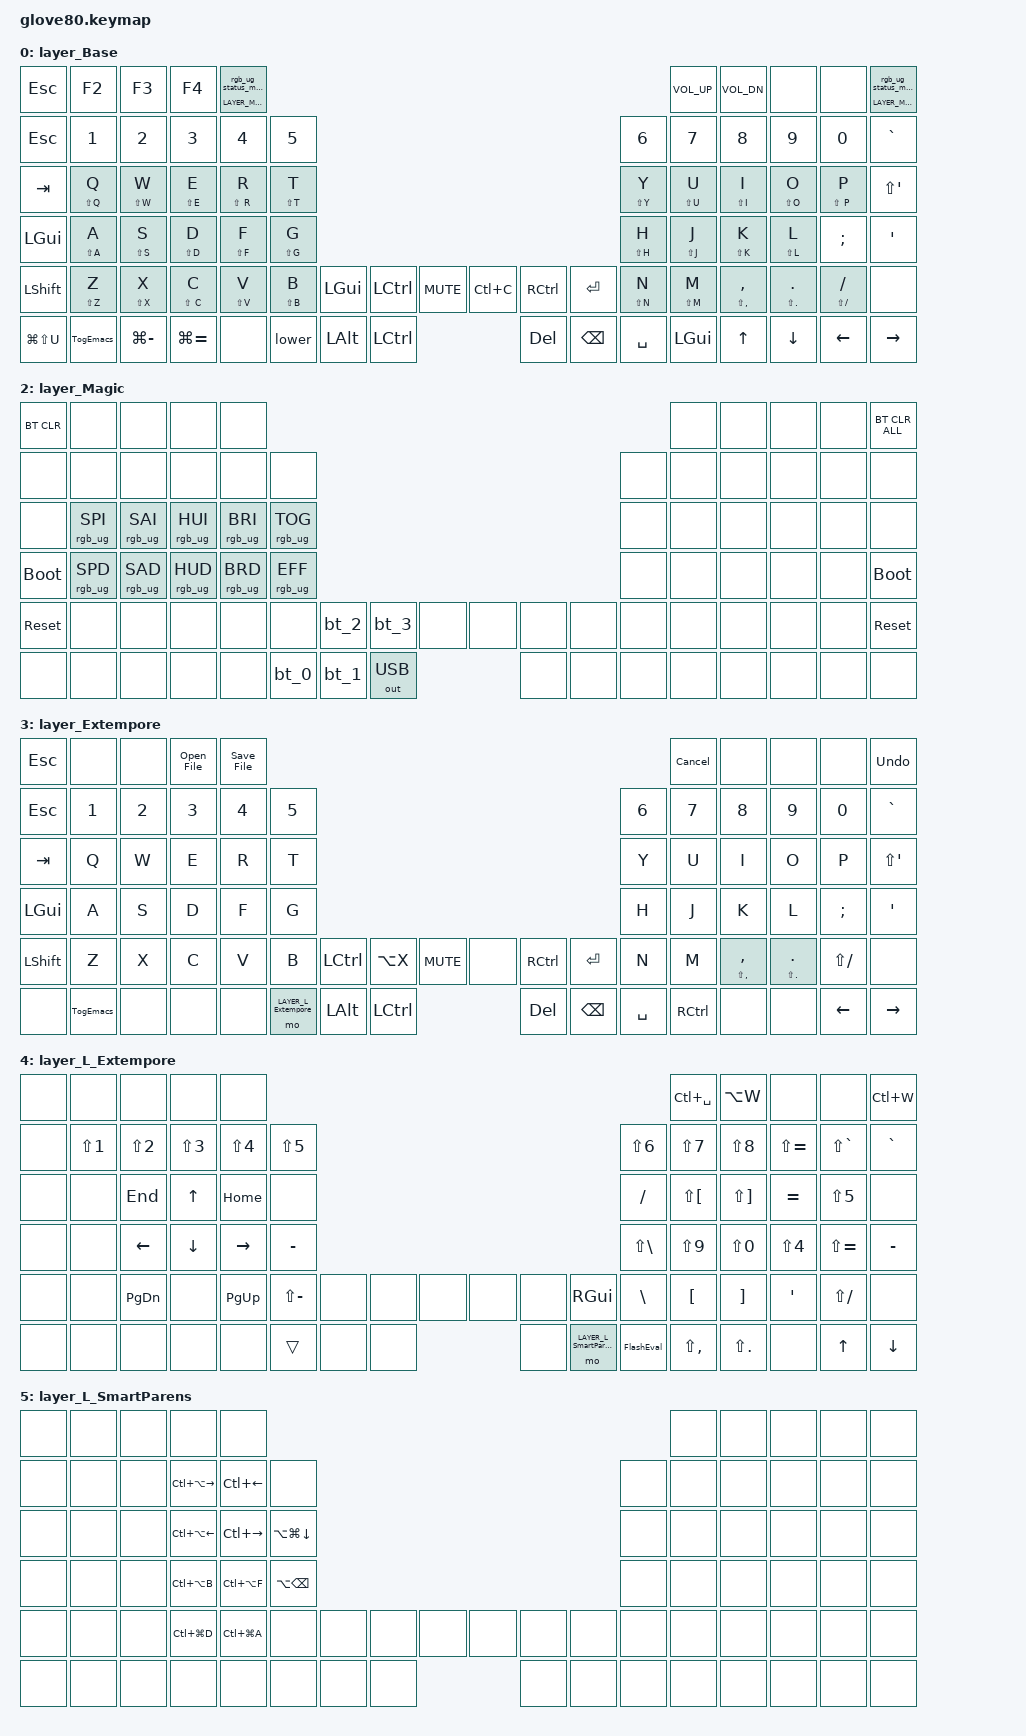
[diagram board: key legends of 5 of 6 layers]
/*
 * Copyright (c) 2020 The ZMK Contributors
 * Copyright (c) 2025 Innaworks Development Limited, trading as MoErgo
 *
 * SPDX-License-Identifier: MIT
 */


/* THIS FILE WAS GENERATED BY GLOVE80 LAYOUT EDITOR
 *
 * This file was generated automatically. You may or may not want to
 * edit it directly.
 *
 *
 * DLM: This is working now Thu Oct 22 21:34:18 AEDT 2026
 *      This has to be processed through the GitHub Repo.
 *      SmartParens modes in this version
 */

#include <behaviors.dtsi>
/* Include all behavior includes needed */
#include <dt-bindings/zmk/outputs.h>
#include <dt-bindings/zmk/keys.h>
#include <dt-bindings/zmk/bt.h>
#include <dt-bindings/zmk/rgb.h>
//#include <dt-bindings/zmk/rgb_colors.h>

/* On demand includes */


/* Helper Macros, based on https://github.com/urob/zmk-helpers/ */

#pragma once

#define ZMK_HELPER_STRINGIFY(x) #x

// Preprocessor mechanism to overload macros, cf. https://stackoverflow.com/a/27051616/6114651
#define VARGS_(_10, _9, _8, _7, _6, _5, _4, _3, _2, _1, N, ...) N
#define VARGS(...) VARGS_(__VA_ARGS__, 10, 9, 8, 7, 6, 5, 4, 3, 2, 1, 0)
#define CONCAT_(a, b) a##b
#define CONCAT(a, b) CONCAT_(a, b)

#define ZMK_BEHAVIOR_CORE_tap_dance  \
    compatible = "zmk,behavior-tap-dance"; \
    #binding-cells = <0>

#define ZMK_BEHAVIOR(name, type, ...) \
    name: name { \
        ZMK_BEHAVIOR_CORE_ ## type; \
        __VA_ARGS__ \
    };

#define ZMK_TAP_DANCE(name, ...) \
    ZMK_BEHAVIOR(name, tap_dance, __VA_ARGS__)

#define ZMK_TD_LAYER(name, layer) \
    ZMK_TAP_DANCE(name, \
        tapping-term-ms = <200>; \
        bindings = <&mo layer>, <&to layer>; \
)

/* Environment and metadata defines */
#define KB_TYPE_GLOVE_80 1
#define KB_TYPE_GO_60    2

#define KB_TYPE          KB_TYPE_GLOVE_80
#define EDITOR_LAYOUT_OS 'M'
#define EDITOR_HOST_OS   'M'

/* Automatically generated layer name defines */
#define LAYER_Base 0
#define LAYER_Lower 1
#define LAYER_Magic 2
#define LAYER_Extempore 3
#define LAYER_L_Extempore 4
#define LAYER_L_SmartParens 5

/* To deal with the situation where there is no Lower layer, to keep &lower happy */
#ifndef LAYER_Lower
#define LAYER_Lower 0
#endif

/* Custom Device-tree */
// ==== PER-KEY-RGB <section begins> =====

/* Include all behavior includes needed */

#include <behaviors.dtsi>
#include <dt-bindings/zmk/outputs.h>
#include <dt-bindings/zmk/keys.h>
#include <dt-bindings/zmk/bt.h>
//#include <dt-bindings/zmk/rgb.h>
#include <dt-bindings/zmk/rgb_colors.h>

/{
    underglow-layer {
        compatible  = "zmk,underglow-layer";
        Base {
            bindings = <
                &ug ___ &ug ___ &ug ___ &ug ___ &ug ___ &ug ___ &ug ___ &ug ___ &ug ___ &ug ___
                &ug ___ &ug ___ &ug ___ &ug ___ &ug ___ &ug ___ &ug ___ &ug ___ &ug ___ &ug ___ &ug ___ &ug ___
                &ug ___ &ug ___ &ug ___ &ug ___ &ug ___ &ug ___                                                  &ug ___ &ug ___ &ug ___ &ug ___ &ug ___ &ug ___
                &ug ___ &ug ___ &ug ___ &ug ___ &ug ___ &ug ___                                                  &ug ___ &ug ___ &ug ___ &ug ___ &ug ___ &ug ___
                &ug ___ &ug ___ &ug ___ &ug ___ &ug ___ &ug ___ &ug ___ &ug ___ &ug ___  &ug ___ &ug ___ &ug ___ &ug ___ &ug ___ &ug ___ &ug ___ &ug ___ &ug ___
                &ug ___ &ug ___ &ug ___ &ug ___ &ug ___         &ug ___ &ug ___ &ug ___  &ug ___ &ug ___ &ug ___         &ug ___ &ug ___ &ug ___ &ug ___ &ug ___
                >;

            layer-id = <LAYER_Base>;
        };

        Lower {
            bindings = <
                &ug ___ &ug ___ &ug ___ &ug ___ &ug ___ &ug ___ &ug ___ &ug ___ &ug ___ &ug ___
                &ug ___ &ug ___ &ug ___ &ug ___ &ug ___ &ug ___ &ug ___ &ug ___ &ug ___ &ug ___ &ug ___ &ug ___
                &ug ___ &ug ___ &ug ___ &ug ___ &ug ___ &ug ___                                                  &ug ___ &ug ___ &ug ___ &ug ___ &ug ___ &ug ___
                &ug ___ &ug ___ &ug ___ &ug ___ &ug ___ &ug ___                                                  &ug ___ &ug ___ &ug ___ &ug ___ &ug ___ &ug ___
                &ug ___ &ug ___ &ug ___ &ug ___ &ug ___ &ug ___ &ug ___ &ug ___ &ug ___  &ug ___ &ug ___ &ug ___ &ug ___ &ug ___ &ug ___ &ug ___ &ug ___ &ug ___
                &ug ___ &ug ___ &ug ___ &ug ___ &ug ___         &ug ___ &ug ___ &ug ___  &ug ___ &ug ___ &ug ___         &ug ___ &ug ___ &ug ___ &ug ___ &ug ___
                >;

            layer-id = <LAYER_Lower>;
        };
        Extempore {
            bindings = <
                &ug ___ &ug ___ &ug 0xFF0000 &ug ___ &ug ___ &ug ___ &ug ___ &ug 0xFF0000 &ug ___ &ug ___
                &ug ___ &ug ___ &ug ___ &ug ___ &ug ___ &ug ___ &ug ___ &ug ___ &ug ___ &ug ___ &ug ___ &ug ___
                &ug ___ &ug ___ &ug ___ &ug ___ &ug ___ &ug ___                      &ug ___ &ug ___ &ug ___ &ug ___ &ug ___ &ug ___
               &ug ___ &ug ___ &ug ___ &ug ___ &ug ___ &ug ___                      &ug ___ &ug ___ &ug ___ &ug ___ &ug ___ &ug ___
                &ug ___ &ug ___ &ug ___ &ug ___ &ug ___ &ug ___ &ug ___ &ug ___ &ug ___  &ug ___ &ug ___ &ug ___ &ug ___ &ug ___ &ug ___ &ug ___ &ug ___ &ug ___
               &ug ___ &ug ___ &ug ___ &ug ___ &ug ___         &ug ___ &ug ___ &ug ___  &ug ___ &ug ___ &ug ___         &ug ___ &ug ___ &ug ___ &ug ___ &ug ___
                >;

            layer-id = <LAYER_Extempore>;
        };
        L_Extempore {
            bindings = <
                &ug ___ &ug ___ &ug ___ &ug 0xFF0000 &ug ___ &ug ___ &ug 0xFF0000 &ug ___ &ug ___ &ug ___
                &ug ___ &ug ___ &ug ___ &ug ___ &ug ___ &ug ___ &ug ___ &ug ___ &ug ___ &ug ___ &ug ___ &ug ___
                &ug ___ &ug ___ &ug ___ &ug ___ &ug ___ &ug ___                                                  &ug ___ &ug ___ &ug ___ &ug ___ &ug ___ &ug ___
                &ug ___ &ug ___ &ug ___ &ug ___ &ug ___ &ug ___                                                  &ug ___ &ug ___ &ug ___ &ug ___ &ug ___ &ug ___
                &ug ___ &ug ___ &ug ___ &ug ___ &ug ___ &ug ___ &ug ___ &ug ___ &ug ___  &ug ___ &ug ___ &ug ___ &ug ___ &ug ___ &ug ___ &ug ___ &ug ___ &ug ___
                &ug ___ &ug ___ &ug ___ &ug ___ &ug ___         &ug ___ &ug ___ &ug ___  &ug ___ &ug ___ &ug ___         &ug ___ &ug ___ &ug ___ &ug ___ &ug ___
                >;

            layer-id = <LAYER_L_Extempore>;
        };
        L_SmartParens {
            bindings = <
                &ug ___ &ug ___ &ug 0xFF0000   &ug 0xFF0000 &ug ___ &ug ___ &ug 0xFF0000 &ug 0xFF0000 &ug ___ &ug ___
                &ug ___ &ug ___ &ug ___ &ug ___ &ug ___ &ug ___ &ug ___ &ug ___ &ug ___ &ug ___ &ug ___ &ug ___
                &ug ___ &ug ___ &ug ___ &ug ___ &ug ___ &ug ___                                                  &ug ___ &ug ___ &ug ___ &ug ___ &ug ___ &ug ___
                &ug ___ &ug ___ &ug ___ &ug ___ &ug ___ &ug ___                                                  &ug ___ &ug ___ &ug ___ &ug ___ &ug ___ &ug ___
                &ug ___ &ug ___ &ug ___ &ug ___ &ug ___ &ug ___ &ug ___ &ug ___ &ug ___  &ug ___ &ug ___ &ug ___ &ug ___ &ug ___ &ug ___ &ug ___ &ug ___ &ug ___
                &ug ___ &ug ___ &ug ___ &ug ___ &ug ___         &ug ___ &ug ___ &ug ___  &ug ___ &ug ___ &ug ___         &ug ___ &ug ___ &ug ___ &ug ___ &ug ___
                >;

            layer-id = <LAYER_L_SmartParens>;
        };        // Add more RGB :wait-mslayers here
    };
};

// ==== PER-KEY-RGB <section ends> =====

/* Input Listeners */


/* System behavior and Macros */
/ {
    behaviors {
        ZMK_TD_LAYER(lower, LAYER_Lower)
    };
};

/ {
    macros {
        rgb_ug_status_macro: rgb_ug_status_macro {
            label = "RGB_UG_STATUS";
            compatible = "zmk,behavior-macro";
            #binding-cells = <0>;
            bindings
                = <&rgb_ug RGB_STATUS>;
        };
    };
};


/ {
#ifdef BT_DISC_CMD
    behaviors {
        bt_0: bt_0 {
            compatible = "zmk,behavior-tap-dance";
            label = "BT_0";
            #binding-cells = <0>;
            tapping-term-ms = <200>;
            bindings = <&bt_select_0>, <&bt BT_DISC 0>;
        };
        bt_1: bt_1 {
            compatible = "zmk,behavior-tap-dance";
            label = "BT_1";
            #binding-cells = <0>;
            tapping-term-ms = <200>;
            bindings = <&bt_select_1>, <&bt BT_DISC 1>;
        };
        bt_2: bt_2 {
            compatible = "zmk,behavior-tap-dance";
            label = "BT_2";
            #binding-cells = <0>;
            tapping-term-ms = <200>;
            bindings = <&bt_select_2>, <&bt BT_DISC 2>;
        };
        bt_3: bt_3 {
            compatible = "zmk,behavior-tap-dance";
            label = "BT_3";
            #binding-cells = <0>;
            tapping-term-ms = <200>;
            bindings = <&bt_select_3>, <&bt BT_DISC 3>;
        };
    };
    macros {
        bt_select_0: bt_select_0 {
            label = "BT_SELECT_0";
            compatible = "zmk,behavior-macro";
            #binding-cells = <0>;
            bindings
                = <&out OUT_BLE>,
                  <&bt BT_SEL 0>;
        };
        bt_select_1: bt_select_1 {
            label = "BT_SELECT_1";
            compatible = "zmk,behavior-macro";
            #binding-cells = <0>;
            bindings
                = <&out OUT_BLE>,
                  <&bt BT_SEL 1>;
        };
        bt_select_2: bt_select_2 {
            label = "BT_SELECT_2";
            compatible = "zmk,behavior-macro";
            #binding-cells = <0>;
            bindings
                = <&out OUT_BLE>,
                  <&bt BT_SEL 2>;
        };
        bt_select_3: bt_select_3 {
            label = "BT_SELECT_3";
            compatible = "zmk,behavior-macro";
            #binding-cells = <0>;
            bindings
                = <&out OUT_BLE>,
                  <&bt BT_SEL 3>;
        };
    };
#else
    macros {
        bt_0: bt_0 {
            label = "BT_0";
            compatible = "zmk,behavior-macro";
            #binding-cells = <0>;
            bindings
                = <&out OUT_BLE>,
                  <&bt BT_SEL 0>;
        };
        bt_1: bt_1 {
            label = "BT_1";
            compatible = "zmk,behavior-macro";
            #binding-cells = <0>;
            bindings
                = <&out OUT_BLE>,
                  <&bt BT_SEL 1>;
        };
        bt_2: bt_2 {
            label = "BT_2";
            compatible = "zmk,behavior-macro";
            #binding-cells = <0>;
            bindings
                = <&out OUT_BLE>,
                  <&bt BT_SEL 2>;
        };
        bt_3: bt_3 {
            label = "BT_3";
            compatible = "zmk,behavior-macro";
            #binding-cells = <0>;
            bindings
                = <&out OUT_BLE>,
                  <&bt BT_SEL 3>;
        };
    };
#endif
};

/ {
    behaviors {
        magic: magic {
            compatible = "zmk,behavior-hold-tap";
            label = "MAGIC_HOLD_TAP";
            #binding-cells = <2>;
            flavor = "tap-preferred";
            tapping-term-ms = <200>;
            bindings = <&mo>, <&rgb_ug_status_macro>;
        };
    };
};


/* Key positions */

#define POS_LH_C6R1 0
#define POS_LH_C5R1 1
#define POS_LH_C4R1 2
#define POS_LH_C3R1 3
#define POS_LH_C2R1 4
#define POS_RH_C2R1 5
#define POS_RH_C3R1 6
#define POS_RH_C4R1 7
#define POS_RH_C5R1 8
#define POS_RH_C6R1 9
#define POS_LH_C6R2 10
#define POS_LH_C5R2 11
#define POS_LH_C4R2 12
#define POS_LH_C3R2 13
#define POS_LH_C2R2 14
#define POS_LH_C1R2 15
#define POS_RH_C1R2 16
#define POS_RH_C2R2 17
#define POS_RH_C3R2 18
#define POS_RH_C4R2 19
#define POS_RH_C5R2 20
#define POS_RH_C6R2 21
#define POS_LH_C6R3 22
#define POS_LH_C5R3 23
#define POS_LH_C4R3 24
#define POS_LH_C3R3 25
#define POS_LH_C2R3 26
#define POS_LH_C1R3 27
#define POS_RH_C1R3 28
#define POS_RH_C2R3 29
#define POS_RH_C3R3 30
#define POS_RH_C4R3 31
#define POS_RH_C5R3 32
#define POS_RH_C6R3 33
#define POS_LH_C6R4 34
#define POS_LH_C5R4 35
#define POS_LH_C4R4 36
#define POS_LH_C3R4 37
#define POS_LH_C2R4 38
#define POS_LH_C1R4 39
#define POS_RH_C1R4 40
#define POS_RH_C2R4 41
#define POS_RH_C3R4 42
#define POS_RH_C4R4 43
#define POS_RH_C5R4 44
#define POS_RH_C6R4 45
#define POS_LH_C6R5 46
#define POS_LH_C5R5 47
#define POS_LH_C4R5 48
#define POS_LH_C3R5 49
#define POS_LH_C2R5 50
#define POS_LH_C1R5 51
#define POS_LH_T1 52
#define POS_LH_T2 53
#define POS_LH_T3 54
#define POS_RH_T3 55
#define POS_RH_T2 56
#define POS_RH_T1 57
#define POS_RH_C1R5 58
#define POS_RH_C2R5 59
#define POS_RH_C3R5 60
#define POS_RH_C4R5 61
#define POS_RH_C5R5 62
#define POS_RH_C6R5 63
#define POS_LH_C6R6 64
#define POS_LH_C5R6 65
#define POS_LH_C4R6 66
#define POS_LH_C3R6 67
#define POS_LH_C2R6 68
#define POS_LH_T4 69
#define POS_LH_T5 70
#define POS_LH_T6 71
#define POS_RH_T6 72
#define POS_RH_T5 73
#define POS_RH_T4 74
#define POS_RH_C2R6 75
#define POS_RH_C3R6 76
#define POS_RH_C4R6 77
#define POS_RH_C5R6 78
#define POS_RH_C6R6 79


/* Custom Defined Behaviors */
/ {
behaviors {
    as: auto_shift {
        compatible = "zmk,behavior-hold-tap";
        label = "AUTO_SHIFT";
        #binding-cells = <2>;
        tapping_term_ms = <350>;
        quick_tap_ms = <0>;
        flavor = "tap-preferred";
        bindings = <&kp>, <&kp>;
    };
    es: execute_snippet {
        compatible = "zmk,behavior-hold-tap";
        label = "EXECUTE_SNIPPET";
        #binding-cells = <2>;
        tapping_term_ms = <350>;
        quick_tap_ms = <0>;
        flavor = "tap-preferred";
        bindings = <&execute_snippet>, <&kp>;
    };
    ac: app_cycle {
        compatible = "zmk,behavior-hold-tap";
        label = "APP_CYCLE";
        #binding-cells = <2>;
        tapping_term_ms = <10>;
        quick_tap_ms = <0>;
        flavor = "tap-preferred";
        bindings = <&execute_snippet>, <&kp>;
    };
};
};

/* Generated input processors */


/* Automatically generated macro definitions */
/ {
    macros {

        // Auto Shift
        execute_snippet: execute_snippet {
            label = "&EXECUTE_SNIPPET";
            compatible = "zmk,behavior-macro";
            #binding-cells = <0>;
            bindings = <&kp LSHFT>
                , <&kp N>
                , <&macro_tap>;
        };

        // Undo
        Undo: Undo {
            label = "&UNDO";
            compatible = "zmk,behavior-macro";
            #binding-cells = <0>;
            tap-ms = <1>;
            wait-ms = <1>;
            bindings = <&kp LC(X)>
                , <&kp U>;
        };

        // Open File
        Open_File: Open_File {
            label = "&OPEN_FILE";
            compatible = "zmk,behavior-macro";
            #binding-cells = <0>;
            tap-ms = <1>;
            wait-ms = <1>;
            bindings = <&kp LC(X)>
                , <&kp LC(F)>;
        };

        // Save File
        Save_File: Save_File {
            label = "&SAVE_FILE";
            compatible = "zmk,behavior-macro";
            #binding-cells = <0>;
            tap-ms = <1>;
            wait-ms = <1>;
            bindings = <&kp LC(X)>
                , <&kp LC(S)>;
        };

        // To Layer 3 & 4 for Emacs/Extempore functions.
        TogEmacs: TogEmacs {
            label = "&TOGEMACS";
            compatible = "zmk,behavior-macro";
            #binding-cells = <0>;
            bindings = <&tog LAYER_Extempore>;
        };

//        TogEmacs: TogEmacs {
//            label = "&TOGEMACS";
//            compatible = "zmk,behavior-macro";
//            #binding-cells = <0>;
//            tap-ms = <1>;
//            wait-ms = <1>;
//            bindings = <&tog LAYER_Extempore>;
//                , <&macro_pause_for_release>
//        };

        FlashEval: FlashEval {
            label = "&FLASHEVAL";
            compatible = "zmk,behavior-macro";
            #binding-cells = <0>;
            tap-ms = <1>;
            wait-ms = <1>;
            bindings = <&rgb_ug RGB_TOG>
                , <&macro_pause_for_release>
                , <&rgb_ug RGB_TOG>
                , <&kp LA(LC(X))>;
        };

        // Auto Shift
        app_cycle: app_cycle {
            label = "&APP_CYCLE";
            compatible = "zmk,behavior-macro";
            #binding-cells = <0>;
            tap-ms = <1>;
            wait-ms = <500>;
            bindings = <&kp LGUI>
                , <&kp TAB>
                , <&macro_tap>;
        };

        // Save File and Typeset in TexShop
        LaTex_Save: LaTex_Save {
            label = "&LATEX_SAVE";
            compatible = "zmk,behavior-macro";
            #binding-cells = <0>;
            tap-ms = <1>;
            wait-ms = <500>;
            bindings = <&kp LG(S)>
                , <&macro_wait_time 500>
                , <&kp LG(T)>;
        };

        // Cycles through Emacs Windows
        CycleWindows: CycleWindows {
            label = "&CYCLEWINDOWS";
            compatible = "zmk,behavior-macro";
            #binding-cells = <0>;
            bindings = <&kp LC(X)>
                , <&kp O>;
        };

        // Cancel Pending Command
        Cancel: Cancel {
            label = "&CANCEL";
            compatible = "zmk,behavior-macro";
            #binding-cells = <0>;
            bindings = <&kp LC(G)>;
        };
    };
};

/* Automatically generated behavior definitions */
/ {
    behaviors {


        // Homerow Mod for the left index finger - TailorKey.
        // For advanced tuning of HRM values, see: https://docs.google.com/spreadsheets/d/1ESgObQelyz4lnKlfwLYsmofLJulOMK5RdGBsopLe2o8
        HRM_left_index_v1_TKZ: HRM_left_index_v1_TKZ {
            compatible = "zmk,behavior-hold-tap";
            #binding-cells = <2>;
            tapping-term-ms = <170>;
            bindings = <&kp>, <&kp>;
            flavor = "tap-preferred";
            quick-tap-ms = <300>;
            require-prior-idle-ms = <100>;
            hold-trigger-key-positions = <POS_RH_C1R2 POS_RH_C2R2 POS_RH_C2R3 POS_RH_C1R3 POS_RH_C1R4 POS_RH_C2R4 POS_RH_C1R5 POS_RH_C2R5 POS_RH_C3R5 POS_RH_C4R5 POS_RH_C4R4 POS_RH_C3R4 POS_RH_C4R3 POS_RH_C3R3 POS_RH_C4R2 POS_RH_C3R2>;
        };
    };
};

/* Automatically generated combos definitions */


/* Automatically generated keymap */
/ {
    keymap {
        compatible = "zmk,keymap";


        layer_Base {
            bindings = <
       &kp ESC      &kp F2         &kp F3         &kp F4  &magic LAYER_Magic 0                                                                                              &kp C_VOL_UP         &kp C_VOL_DN            &none              &none  &magic LAYER_Magic 0
       &kp ESC      &kp N1         &kp N2         &kp N3  &kp N4       &kp N5                                                                         &kp N6        &kp N7               &kp N8           &kp N9             &kp N0             &kp GRAVE
       &kp TAB  &as LS(Q)Q    &as LS(W) W    &as  LS(E)E  &as LS( R )R &as LS(T) T                                                                    &as LS(Y) Y   &as LS(U) U          &as LS(I) I       &as LS(O)O      &as LS( P ) P  &kp LS(SINGLE_QUOTE)
      &kp LGUI  &as LS(A)A     &as LS(S)S     &as LS(D)D  &as LS(F)F   &as LS(G)G                                                                     &as LS(H)H   &as LS(J) J          &as LS(K) K      &as LS(L) L           &kp SEMI               &kp SQT
     &kp LSHFT  &as LS(Z)Z    &as LS(X) X   &as LS( C) C  &as LS(V) V  &as LS(B) B  &kp LGUI   &kp LCTRL  &kp C_MUTE  &kp LC(C)  &kp RCTRL    &kp RET  &as LS(N) N   &as LS(M) M  &as LS(COMMA) COMMA  &as LS(DOT) DOT  &as LS(FSLH) FSLH                 &none
 &kp LG(LS(U))   &TogEmacs  &kp LG(MINUS)  &kp LG(EQUAL)  &none        &lower  &kp LALT   &kp LCTRL                   &kp DEL   &kp BSPC  &kp SPACE                   &kp LGUI               &kp UP         &kp DOWN           &kp LEFT             &kp RIGHT
            >;
        };

        layer_Lower {
            bindings = <
     &kp F1      &kp F2             &kp F3            &kp F4           &kp F5                                                                                                     &kp F6        &kp F7      &kp F8         &kp F9     &kp F10
 &kp LC(N1)  &kp LC(N2)         &kp LC(N3)        &kp LC(N4)       &kp LC(N5)     &kp LC(N6)                                                                   &kp LS(N6)     &kp LS(N7)    &kp LS(N8)  &kp LS(N3)  &kp LS(GRAVE)   &kp GRAVE
     &trans       &none            &kp END      &kp UP_ARROW         &kp HOME     &kp LC(N7)                                                                     &kp FSLH   &kp LS(LBKT)  &kp LS(RBKT)   &kp EQUAL     &kp LS(N5)  &kp LS(N1)
     &trans       &none     &kp LEFT_ARROW    &kp DOWN_ARROW  &kp RIGHT_ARROW      &kp MINUS                                                                 &kp LS(BSLH)     &kp LS(N9)    &kp LS(N0)  &kp LS(N4)  &kp LS(EQUAL)       &none
     &trans       &none          &kp PG_DN             &none        &kp PG_UP  &kp LS(MINUS)  &kp LC(N8)   &none   &none  &kp LG(S)  &LaTex_Save  &kp LG(N)      &kp BSLH       &kp LBKT      &kp RBKT     &kp SQT       &kp LEFT   &kp RIGHT
   &kp CAPS       &none  &kp (LG(LS (N4)))  &kp (LG(LS(N3)))        &kp LC(C)                     &trans   &none   &none      &none        &none      &none                &kp LS(COMMA)   &kp LS(DOT)       &none         &kp UP    &kp DOWN
            >;
        };

        layer_Magic {
            bindings = <
  &bt BT_CLR            &none            &none            &none            &none                                                                                  &none   &none   &none   &none  &bt BT_CLR_ALL
       &none            &none            &none            &none            &none            &none                                                         &none   &none   &none   &none   &none           &none
       &none  &rgb_ug RGB_SPI  &rgb_ug RGB_SAI  &rgb_ug RGB_HUI  &rgb_ug RGB_BRI  &rgb_ug RGB_TOG                                                         &none   &none   &none   &none   &none           &none
 &bootloader  &rgb_ug RGB_SPD  &rgb_ug RGB_SAD  &rgb_ug RGB_HUD  &rgb_ug RGB_BRD  &rgb_ug RGB_EFF                                                         &none   &none   &none   &none   &none     &bootloader
  &sys_reset            &none            &none            &none            &none            &none   &bt_2   &bt_3         &none   &none   &none   &none   &none   &none   &none   &none   &none      &sys_reset
       &none            &none            &none            &none            &none                    &bt_0   &bt_1  &out OUT_USB   &none   &none   &none           &none   &none   &none   &none           &none
            >;
        };

        layer_Extempore {
            bindings = <
   &kp ESC      &none   &none  &Open_File  &Save_File                                                                                                 &Cancel                &none            &none         &none                 &Undo
   &kp ESC     &kp N1  &kp N2      &kp N3      &kp N4  &kp N5                                                                               &kp N6     &kp N7               &kp N8           &kp N9        &kp N0             &kp GRAVE
   &kp TAB      &kp Q   &kp W       &kp E       &kp R   &kp T                                                                                &kp Y      &kp U                &kp I            &kp O         &kp P  &kp LS(SINGLE_QUOTE)
  &kp LGUI      &kp A   &kp S       &kp D       &kp F   &kp G                                                                                &kp H      &kp J                &kp K            &kp L      &kp SEMI               &kp SQT
 &kp LSHFT      &kp Z   &kp X       &kp C       &kp V   &kp B              &kp LCTRL  &kp LA(X)  &kp C_MUTE    &none  &kp RCTRL    &kp RET   &kp N      &kp M  &as LS(COMMA) COMMA  &as LS(DOT) DOT  &kp LS(FSLH)                 &none
     &none  &TogEmacs   &none       &none       &none          &mo LAYER_L_Extempore   &kp LALT   &kp LCTRL  &kp DEL   &kp BSPC  &kp SPACE          &kp RCTRL                &none            &none      &kp LEFT             &kp RIGHT
            >;
        };

        layer_L_Extempore {
            bindings = <
  &none       &none           &none           &none            &none                                                                                      &kp LC(SPACE)     &kp LA(W)          &none          &none  &kp LC(W)
  &none  &kp LS(N1)      &kp LS(N2)      &kp LS(N3)       &kp LS(N4)     &kp LS(N5)                                                           &kp LS(N6)     &kp LS(N7)    &kp LS(N8)  &kp LS(EQUAL)  &kp LS(GRAVE)  &kp GRAVE
  &none       &none         &kp END    &kp UP_ARROW         &kp HOME          &none                                                             &kp FSLH   &kp LS(LBKT)  &kp LS(RBKT)      &kp EQUAL     &kp LS(N5)      &none
  &none       &none  &kp LEFT_ARROW  &kp DOWN_ARROW  &kp RIGHT_ARROW      &kp MINUS                                                         &kp LS(BSLH)     &kp LS(N9)    &kp LS(N0)     &kp LS(N4)  &kp LS(EQUAL)  &kp MINUS
  &none       &none       &kp PG_DN           &none        &kp PG_UP  &kp LS(MINUS)   &none   &none   &none   &none      &none       &kp RGUI      &kp BSLH       &kp LBKT      &kp RBKT        &kp SQT   &kp LS(FSLH)      &none
  &none       &none           &none           &none            &none                 &trans   &none   &none   &none   &mo LAYER_L_SmartParens  &FlashEval                &kp LS(COMMA)   &kp LS(DOT)          &none         &kp UP   &kp DOWN
            >;
        };

        layer_L_SmartParens {
            bindings = <
  &none   &none   &none              &none          &none                                                                             &none   &none   &none   &none   &none
  &none   &none   &none  &kp LC(LA(RIGHT))   &kp LC(LEFT)             &none                                                   &none   &none   &none   &none   &none   &none
  &none   &none   &none   &kp LC(LA(LEFT))  &kp LC(RIGHT)  &kp LA(LG(DOWN))                                                   &none   &none   &none   &none   &none   &none
  &none   &none   &none      &kp LC(LA(B))  &kp LC(LA(F))      &kp LA(BSPC)                                                   &none   &none   &none   &none   &none   &none
  &none   &none   &none      &kp LC(LG(D))  &kp LC(LG(A))             &none   &none   &none   &none   &none   &none   &none   &none   &none   &none   &none   &none   &none
  &none   &none   &none              &none          &none                     &none   &none   &none   &none   &none   &none           &none   &none   &none   &none   &none
            >;
        };

    };
};
